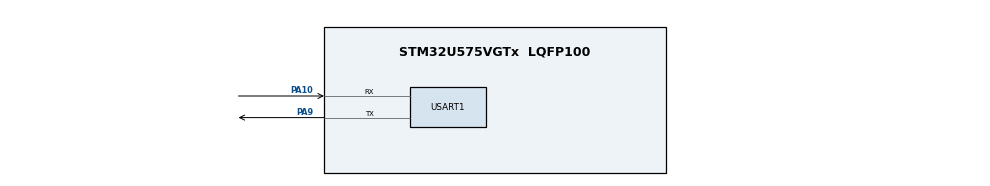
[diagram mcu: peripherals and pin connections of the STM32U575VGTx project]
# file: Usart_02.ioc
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CORTEX_M33_NS.userName=CORTEX_M33
Mcu.Family=STM32U5
Mcu.Name=STM32U575VGTx
Mcu.Package=LQFP100
NVIC.PriorityGroup=NVIC_PRIORITYGROUP_4
NVIC.USART1_IRQn=true\:0\:0\:false\:false\:true\:true\:true\:true
PA10.Mode=Asynchronous
PA10.Signal=USART1_RX
PA13\ (JTMS/SWDIO).Mode=Serial_Wire
PA13\ (JTMS/SWDIO).Signal=DEBUG_JTMS-SWDIO
PA14\ (JTCK/SWCLK).Mode=Serial_Wire
PA14\ (JTCK/SWCLK).Signal=DEBUG_JTCK-SWCLK
PA9.Mode=Asynchronous
PA9.Signal=USART1_TX
ProjectManager.HeapSize=0x200
ProjectManager.StackSize=0x400
ProjectManager.TargetToolchain=MDK-ARM V5.39
RCC.ADCFreq_Value=16000000
RCC.EPOD_VALUE=16000000
RCC.HSE_VALUE=16000000
RCC.HSI48_VALUE=48000000
RCC.HSI_VALUE=16000000
RCC.LSE_VALUE=32768
RCC.LSIDIV_VALUE=32000
RCC.MSI_VALUE=4000000
RCC.PLLSourceVirtual=RCC_PLLSOURCE_HSI
RCC.USBFreq_Value=48000000
RCC.VCOOutputFreq_Value=2064000000
USART1.VirtualMode-Asynchronous=VM_ASYNC
VP_LPBAMQUEUE_VS_QUEUE.Mode=QUEUEMODE
VP_LPBAM_VS_SIG1.Mode=SmartRun
VP_LPBAM_VS_SIG4.Mode=LPDMA1
VP_MEMORYMAP_VS_MEMORYMAP.Mode=CurAppReg
VP_PWR_VS_SECSignals.Mode=Security/Privilege
board=custom

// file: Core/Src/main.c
/* USER CODE BEGIN Header */
/**
  ******************************************************************************
  * @file           : main.c
  * @brief          : Main program body
  ******************************************************************************
  * @attention
  *
  * Copyright (c) 2026 STMicroelectronics.
  * All rights reserved.
  *
  * This software is licensed under terms that can be found in the LICENSE file
  * in the root directory of this software component.
  * If no LICENSE file comes with this software, it is provided AS-IS.
  *
  ******************************************************************************
  */
/* USER CODE END Header */
#include "main.h"

/* USER CODE BEGIN Includes */
#include <stdio.h>
/* USER CODE END Includes */

UART_HandleTypeDef huart1;

/* USER CODE BEGIN PV */
static uint8_t          rx_byte = 0;
static volatile uint8_t rx_flag = 0;

/* USER CODE END PV */

void SystemClock_Config(void);
static void MX_GPIO_Init(void);
static void MX_USART1_UART_Init(void);

/* USER CODE BEGIN 0 */

/* Keil MicroLIB printf 重定向 */
int fputc(int ch, FILE *f)
{
    (void)f;
    HAL_UART_Transmit(&huart1, (uint8_t *)&ch, 1, HAL_MAX_DELAY);
    return ch;
}

/* USER CODE END 0 */

int main(void)
{

  /* MCU Configuration--------------------------------------------------------*/

  /* Reset of all peripherals, Initializes the Flash interface and the Systick. */
  HAL_Init();

  /* Configure the system clock */
  SystemClock_Config();

  /* Initialize all configured peripherals */
  MX_GPIO_Init();
  MX_USART1_UART_Init();
  /* USER CODE BEGIN 2 */

	HAL_Delay(100);
	HAL_UART_Receive_IT(&huart1, &rx_byte, 1);
	printf("就绪，请发送字符：\r\n");

  /* USER CODE END 2 */

  /* Infinite loop */
  while (1)
  {

    /* USER CODE BEGIN 3 */
		    if (rx_flag)
        {
            rx_flag = 0;

            /*
             * 收到字符 → 格式化成 "0xHH\r\n" 发回
             * 例如收到 'A'(0x41) → 回复 "0x41\r\n"
             */
						printf("0x%02X\r\n", rx_byte);
        }

  }
  /* USER CODE END 3 */
}

void SystemClock_Config(void)
{
  RCC_OscInitTypeDef RCC_OscInitStruct = {0};
  RCC_ClkInitTypeDef RCC_ClkInitStruct = {0};

  /** Configure the main internal regulator output voltage
  */
  if (HAL_PWREx_ControlVoltageScaling(PWR_REGULATOR_VOLTAGE_SCALE4) != HAL_OK)
  {
    Error_Handler();
  }

  /** Initializes the CPU, AHB and APB buses clocks
  */
  RCC_OscInitStruct.OscillatorType = RCC_OSCILLATORTYPE_MSI;
  RCC_OscInitStruct.MSIState = RCC_MSI_ON;
  RCC_OscInitStruct.MSICalibrationValue = RCC_MSICALIBRATION_DEFAULT;
  RCC_OscInitStruct.MSIClockRange = RCC_MSIRANGE_4;
  RCC_OscInitStruct.PLL.PLLState = RCC_PLL_NONE;
  if (HAL_RCC_OscConfig(&RCC_OscInitStruct) != HAL_OK)
  {
    Error_Handler();
  }

  /** Initializes the CPU, AHB and APB buses clocks
  */
  RCC_ClkInitStruct.ClockType = RCC_CLOCKTYPE_HCLK|RCC_CLOCKTYPE_SYSCLK
                              |RCC_CLOCKTYPE_PCLK1|RCC_CLOCKTYPE_PCLK2
                              |RCC_CLOCKTYPE_PCLK3;
  RCC_ClkInitStruct.SYSCLKSource = RCC_SYSCLKSOURCE_MSI;
  RCC_ClkInitStruct.AHBCLKDivider = RCC_SYSCLK_DIV1;
  RCC_ClkInitStruct.APB1CLKDivider = RCC_HCLK_DIV1;
  RCC_ClkInitStruct.APB2CLKDivider = RCC_HCLK_DIV1;
  RCC_ClkInitStruct.APB3CLKDivider = RCC_HCLK_DIV1;

  if (HAL_RCC_ClockConfig(&RCC_ClkInitStruct, FLASH_LATENCY_0) != HAL_OK)
  {
    Error_Handler();
  }
}

static void MX_USART1_UART_Init(void)
{

  huart1.Instance = USART1;
  huart1.Init.BaudRate = 115200;
  huart1.Init.WordLength = UART_WORDLENGTH_8B;
  huart1.Init.StopBits = UART_STOPBITS_1;
  huart1.Init.Parity = UART_PARITY_NONE;
  huart1.Init.Mode = UART_MODE_TX_RX;
  huart1.Init.HwFlowCtl = UART_HWCONTROL_NONE;
  huart1.Init.OverSampling = UART_OVERSAMPLING_16;
  huart1.Init.OneBitSampling = UART_ONE_BIT_SAMPLE_DISABLE;
  huart1.Init.ClockPrescaler = UART_PRESCALER_DIV1;
  huart1.AdvancedInit.AdvFeatureInit = UART_ADVFEATURE_NO_INIT;
  if (HAL_UART_Init(&huart1) != HAL_OK)
  {
    Error_Handler();
  }
  if (HAL_UARTEx_SetTxFifoThreshold(&huart1, UART_TXFIFO_THRESHOLD_1_8) != HAL_OK)
  {
    Error_Handler();
  }
  if (HAL_UARTEx_SetRxFifoThreshold(&huart1, UART_RXFIFO_THRESHOLD_1_8) != HAL_OK)
  {
    Error_Handler();
  }
  if (HAL_UARTEx_DisableFifoMode(&huart1) != HAL_OK)
  {
    Error_Handler();
  }

}

static void MX_GPIO_Init(void)
{

  /* GPIO Ports Clock Enable */
  __HAL_RCC_GPIOA_CLK_ENABLE();

}

/* USER CODE BEGIN 4 */
void HAL_UART_RxCpltCallback(UART_HandleTypeDef *huart)
{
    if (huart->Instance == USART1)
    {
        rx_flag = 1;                                     /* 告诉主循环：收到数据了 */
        HAL_UART_Receive_IT(&huart1, &rx_byte, 1);      /* 重新开启接收           */
    }
}

/* USER CODE END 4 */

void Error_Handler(void)
{
  __disable_irq();
  while (1)
  {
  }
}
